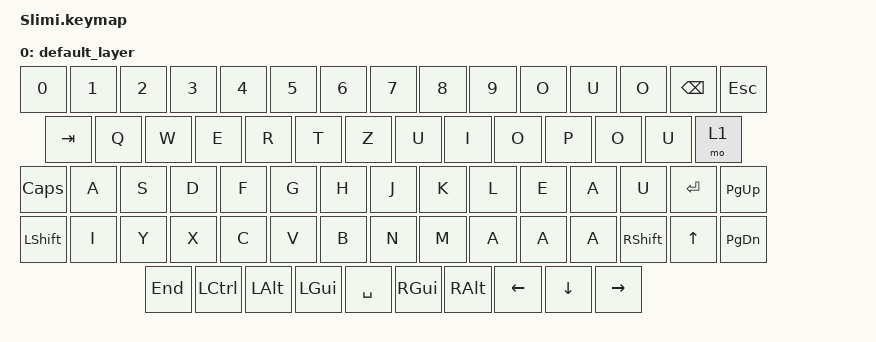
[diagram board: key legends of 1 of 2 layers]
#include <behaviors.dtsi>
#include <dt-bindings/zmk/keys.h>
#include <dt-bindings/zmk/bt.h>

/ {
    keymap {
        compatible = "zmk,keymap";
        default_layer {
            bindings = <
                &kp N0   &kp N1   &kp N2   &kp N3   &kp N4   &kp N5   &kp N6   &kp N7   &kp N8   &kp N9   &kp O   &kp U   &kp O   &kp BSPC   &kp ESC
                &kp TAB    &kp Q   &kp W   &kp E   &kp R   &kp T   &kp Z   &kp U   &kp I   &kp O   &kp P   &kp O   &kp U   &mo 1
                &kp CAPS    &kp A    &kp S    &kp D    &kp F    &kp G    &kp H    &kp J    &kp K    &kp L    &kp E    &kp A    &kp U    &kp ENTER     &kp PG_UP
                &kp LSHIFT    &kp I    &kp Y    &kp X    &kp C    &kp V    &kp B    &kp N    &kp M    &kp A    &kp A    &kp A    &kp RSHIFT    &kp UP    &kp PG_DN
                &kp END    &kp LCTRL    &kp LALT    &kp LGUI    &kp SPACE    &kp RGUI    &kp RALT    &kp LEFT    &kp DOWN    &kp RIGHT
            >;
        };

        bt_layer {
            bindings = <
                &bt BT_SEL 0   &bt BT_SEL 1   &bt BT_SEL 2   &none   &none   &none   &none   &none   &none   &none   &none   &none   &none   &bt BT_CLR   &none
                &none     &none   &none   &none   &none   &none   &none   &none   &none   &none   &none   &none                     &none
                &none      &none   &none   &none   &none   &none   &none   &none   &none   &none   &none   &none   &none   &bootloader    &none
                &none   &none   &none   &none   &none   &none   &none   &none   &none   &none   &none   &none   &none       &none   &none
                &none   &none   &none   &none                       &none                           &none   &none   &none   &none   &none
            >;
        };
    };
};
